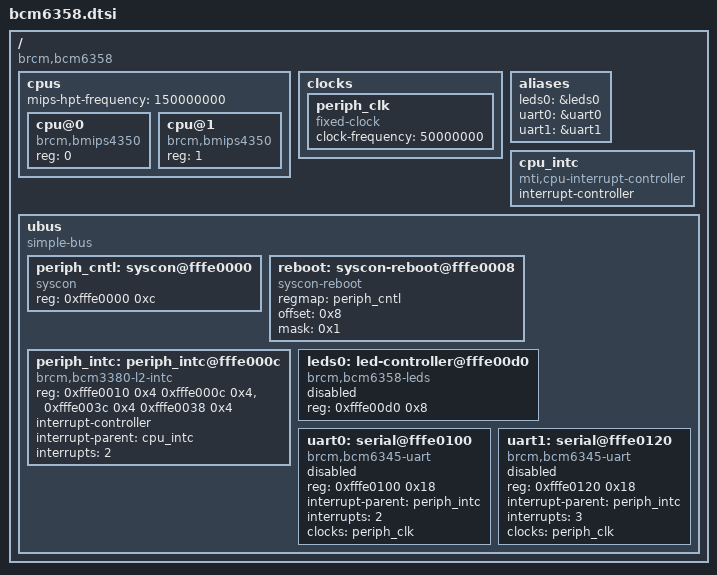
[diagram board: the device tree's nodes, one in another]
/ {
	#address-cells = <1>;
	#size-cells = <1>;
	compatible = "brcm,bcm6358";

	cpus {
		#address-cells = <1>;
		#size-cells = <0>;

		mips-hpt-frequency = <150000000>;

		cpu@0 {
			compatible = "brcm,bmips4350";
			device_type = "cpu";
			reg = <0>;
		};

		cpu@1 {
			compatible = "brcm,bmips4350";
			device_type = "cpu";
			reg = <1>;
		};
	};

	clocks {
		periph_clk: periph_clk {
			compatible = "fixed-clock";
			#clock-cells = <0>;
			clock-frequency = <50000000>;
		};
	};

	aliases {
		leds0 = &leds0;
		uart0 = &uart0;
		uart1 = &uart1;
	};

	cpu_intc: cpu_intc {
		#address-cells = <0>;
		compatible = "mti,cpu-interrupt-controller";

		interrupt-controller;
		#interrupt-cells = <1>;
	};

	ubus {
		#address-cells = <1>;
		#size-cells = <1>;

		compatible = "simple-bus";
		ranges;

		periph_cntl: syscon@fffe0000 {
			compatible = "syscon";
			reg = <0xfffe0000 0xc>;
		};

		reboot: syscon-reboot@fffe0008 {
			compatible = "syscon-reboot";
			regmap = <&periph_cntl>;
			offset = <0x8>;
			mask = <0x1>;
		};

		periph_intc: periph_intc@fffe000c {
			compatible = "brcm,bcm3380-l2-intc";
			reg = <0xfffe0010 0x4 0xfffe000c 0x4>,
			      <0xfffe003c 0x4 0xfffe0038 0x4>;

			interrupt-controller;
			#interrupt-cells = <1>;

			interrupt-parent = <&cpu_intc>;
			interrupts = <2>;
		};

		leds0: led-controller@fffe00d0 {
			#address-cells = <1>;
			#size-cells = <0>;
			compatible = "brcm,bcm6358-leds";
			reg = <0xfffe00d0 0x8>;

			status = "disabled";
		};

		uart0: serial@fffe0100 {
			compatible = "brcm,bcm6345-uart";
			reg = <0xfffe0100 0x18>;

			interrupt-parent = <&periph_intc>;
			interrupts = <2>;

			clocks = <&periph_clk>;

			status = "disabled";
		};

		uart1: serial@fffe0120 {
			compatible = "brcm,bcm6345-uart";
			reg = <0xfffe0120 0x18>;

			interrupt-parent = <&periph_intc>;
			interrupts = <3>;

			clocks = <&periph_clk>;

			status = "disabled";
		};
	};
};
